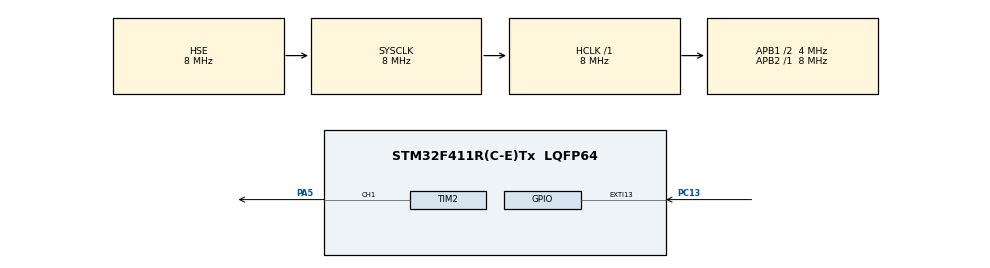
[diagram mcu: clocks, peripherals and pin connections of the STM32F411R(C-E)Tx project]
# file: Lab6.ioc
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Mcu.Family=STM32F4
Mcu.Name=STM32F411R(C-E)Tx
Mcu.Package=LQFP64
NVIC.EXTI15_10_IRQn=true\:0\:0\:false\:false\:true\:true\:true\:true
NVIC.PriorityGroup=NVIC_PRIORITYGROUP_0
NVIC.TIM3_IRQn=true\:0\:0\:false\:false\:true\:true\:true\:true
PA14.GPIO_Label=TCK
PA14.Signal=SYS_JTCK-SWCLK
PA5.Signal=S_TIM2_CH1_ETR
PB3.GPIO_Label=SWO
PB3.Signal=SYS_JTDO-SWO
PC13-ANTI_TAMP.Signal=GPXTI13
PH0\ -\ OSC_IN.Mode=HSE-External-Oscillator
PH0\ -\ OSC_IN.Signal=RCC_OSC_IN
PH1\ -\ OSC_OUT.Mode=HSE-External-Oscillator
PH1\ -\ OSC_OUT.Signal=RCC_OSC_OUT
ProjectManager.HeapSize=0x200
ProjectManager.StackSize=0x400
ProjectManager.TargetToolchain=STM32CubeIDE
RCC.48MHZClocksFreq_Value=25000000
RCC.AHBFreq_Value=8000000
RCC.APB1CLKDivider=RCC_HCLK_DIV2
RCC.APB1Freq_Value=4000000
RCC.APB1TimFreq_Value=8000000
RCC.APB2Freq_Value=8000000
RCC.APB2TimFreq_Value=8000000
RCC.CortexFreq_Value=8000000
RCC.FLatency-AdvancedSettings=FLASH_LATENCY_0
RCC.HCLKFreq_Value=8000000
RCC.HSE_VALUE=8000000
RCC.HSI_VALUE=16000000
RCC.PLLM=8
RCC.PLLN=50
RCC.SYSCLKFreq_VALUE=8000000
RCC.SYSCLKSource=RCC_SYSCLKSOURCE_HSE
RCC.VCOOutputFreq_Value=100000000
SH.S_TIM2_CH1_ETR.0=TIM2_CH1,PWM Generation1 CH1
TIM2.Channel-PWM\ Generation1\ CH1=TIM_CHANNEL_1
TIM2.Period=3999
TIM2.Pulse-PWM\ Generation1\ CH1=0
TIM3.Period=799
TIM3.Prescaler=199
VP_TIM2_VS_ClockSourceINT.Mode=Internal
VP_TIM3_VS_ClockSourceINT.Mode=Internal
board=NUCLEO-F411RE

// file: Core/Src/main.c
/* USER CODE BEGIN Header */
/**
  ******************************************************************************
  * @file           : main.c
  * @brief          : Main program body
  ******************************************************************************
  * @attention
  *
  * Copyright (c) 2026 STMicroelectronics.
  * All rights reserved.
  *
  * This software is licensed under terms that can be found in the LICENSE file
  * in the root directory of this software component.
  * If no LICENSE file comes with this software, it is provided AS-IS.
  *
  ******************************************************************************
  */

/*
 * Варіант 3 (23)
 * Запрограмувати генерацію ШІМ на PA5 (TIM2) з частотою 2 кГц, кнопка PC13 циклічно змінює
duty cycle 0%, 25%, 50%, 75%, 100%

f_pwm = f_tim/((PSC+1)*(ARR+1))
2 000 = 8 000 000/((0+1)*(3999+1))

Duty cycle:
D = CCR1/(ARR+1)

0%
CCR1 = 0
25%
CCR1 = 1000
50%
CCR1 = 2000
75%
CCR1 = 3000
100%
CCR1 = 4000

TIM3 for debounce
T = ((PSK+1)*(ARR+1))/fsck
0.02 = ((199+1)*(799+1))/8 000 000

 */

/* USER CODE END Header */
#include "main.h"

TIM_HandleTypeDef htim2;
TIM_HandleTypeDef htim3;

/* USER CODE BEGIN PV */
uint32_t duty_steps[] = {0, 1000, 2000, 3000, 4000};
int step_index = 0;
int button_pressed_flag = 0;
/* USER CODE END PV */

void SystemClock_Config(void);
static void MX_GPIO_Init(void);
static void MX_TIM2_Init(void);
static void MX_TIM3_Init(void);

/* USER CODE BEGIN 0 */
void HAL_GPIO_EXTI_Callback(uint16_t GPIO_Pin)
{
    if(GPIO_Pin == GPIO_PIN_13)
    {
        if (htim3.State == HAL_TIM_STATE_READY)
        {
            HAL_TIM_Base_Start_IT(&htim3);
        }
    }
}

void HAL_TIM_PeriodElapsedCallback(TIM_HandleTypeDef *htim) {
    if (htim->Instance == TIM3) {
        HAL_TIM_Base_Stop_IT(&htim3);
        button_pressed_flag = 1;
    }
}

/* USER CODE END 0 */

int main(void)
{

  /* MCU Configuration--------------------------------------------------------*/

  /* Reset of all peripherals, Initializes the Flash interface and the Systick. */
  HAL_Init();

  /* Configure the system clock */
  SystemClock_Config();

  /* Initialize all configured peripherals */
  MX_GPIO_Init();
  MX_TIM2_Init();
  MX_TIM3_Init();
  /* USER CODE BEGIN 2 */
  HAL_TIM_PWM_Start(&htim2, TIM_CHANNEL_1);
  /* USER CODE END 2 */

  /* Infinite loop */
  while (1)
  {
    /* USER CODE BEGIN 3 */
	  if(button_pressed_flag)
	  {
		  step_index = (step_index + 1) % 5;
		  __HAL_TIM_SET_COMPARE(&htim2, TIM_CHANNEL_1, duty_steps[step_index]);
		  button_pressed_flag = 0;
	  }
  }
  /* USER CODE END 3 */
}

void SystemClock_Config(void)
{
  RCC_OscInitTypeDef RCC_OscInitStruct = {0};
  RCC_ClkInitTypeDef RCC_ClkInitStruct = {0};

  /** Configure the main internal regulator output voltage
  */
  __HAL_RCC_PWR_CLK_ENABLE();
  __HAL_PWR_VOLTAGESCALING_CONFIG(PWR_REGULATOR_VOLTAGE_SCALE1);

  /** Initializes the RCC Oscillators according to the specified parameters
  * in the RCC_OscInitTypeDef structure.
  */
  RCC_OscInitStruct.OscillatorType = RCC_OSCILLATORTYPE_HSE;
  RCC_OscInitStruct.HSEState = RCC_HSE_ON;
  RCC_OscInitStruct.PLL.PLLState = RCC_PLL_NONE;
  if (HAL_RCC_OscConfig(&RCC_OscInitStruct) != HAL_OK)
  {
    Error_Handler();
  }

  /** Initializes the CPU, AHB and APB buses clocks
  */
  RCC_ClkInitStruct.ClockType = RCC_CLOCKTYPE_HCLK|RCC_CLOCKTYPE_SYSCLK
                              |RCC_CLOCKTYPE_PCLK1|RCC_CLOCKTYPE_PCLK2;
  RCC_ClkInitStruct.SYSCLKSource = RCC_SYSCLKSOURCE_HSE;
  RCC_ClkInitStruct.AHBCLKDivider = RCC_SYSCLK_DIV1;
  RCC_ClkInitStruct.APB1CLKDivider = RCC_HCLK_DIV2;
  RCC_ClkInitStruct.APB2CLKDivider = RCC_HCLK_DIV1;

  if (HAL_RCC_ClockConfig(&RCC_ClkInitStruct, FLASH_LATENCY_0) != HAL_OK)
  {
    Error_Handler();
  }
}

static void MX_TIM2_Init(void)
{

  TIM_ClockConfigTypeDef sClockSourceConfig = {0};
  TIM_MasterConfigTypeDef sMasterConfig = {0};
  TIM_OC_InitTypeDef sConfigOC = {0};

  htim2.Instance = TIM2;
  htim2.Init.Prescaler = 0;
  htim2.Init.CounterMode = TIM_COUNTERMODE_UP;
  htim2.Init.Period = 3999;
  htim2.Init.ClockDivision = TIM_CLOCKDIVISION_DIV1;
  htim2.Init.AutoReloadPreload = TIM_AUTORELOAD_PRELOAD_DISABLE;
  if (HAL_TIM_Base_Init(&htim2) != HAL_OK)
  {
    Error_Handler();
  }
  sClockSourceConfig.ClockSource = TIM_CLOCKSOURCE_INTERNAL;
  if (HAL_TIM_ConfigClockSource(&htim2, &sClockSourceConfig) != HAL_OK)
  {
    Error_Handler();
  }
  if (HAL_TIM_PWM_Init(&htim2) != HAL_OK)
  {
    Error_Handler();
  }
  sMasterConfig.MasterOutputTrigger = TIM_TRGO_RESET;
  sMasterConfig.MasterSlaveMode = TIM_MASTERSLAVEMODE_DISABLE;
  if (HAL_TIMEx_MasterConfigSynchronization(&htim2, &sMasterConfig) != HAL_OK)
  {
    Error_Handler();
  }
  sConfigOC.OCMode = TIM_OCMODE_PWM1;
  sConfigOC.Pulse = 0;
  sConfigOC.OCPolarity = TIM_OCPOLARITY_HIGH;
  sConfigOC.OCFastMode = TIM_OCFAST_DISABLE;
  if (HAL_TIM_PWM_ConfigChannel(&htim2, &sConfigOC, TIM_CHANNEL_1) != HAL_OK)
  {
    Error_Handler();
  }
  HAL_TIM_MspPostInit(&htim2);

}

static void MX_TIM3_Init(void)
{

  TIM_ClockConfigTypeDef sClockSourceConfig = {0};
  TIM_MasterConfigTypeDef sMasterConfig = {0};

  htim3.Instance = TIM3;
  htim3.Init.Prescaler = 199;
  htim3.Init.CounterMode = TIM_COUNTERMODE_UP;
  htim3.Init.Period = 799;
  htim3.Init.ClockDivision = TIM_CLOCKDIVISION_DIV1;
  htim3.Init.AutoReloadPreload = TIM_AUTORELOAD_PRELOAD_DISABLE;
  if (HAL_TIM_Base_Init(&htim3) != HAL_OK)
  {
    Error_Handler();
  }
  sClockSourceConfig.ClockSource = TIM_CLOCKSOURCE_INTERNAL;
  if (HAL_TIM_ConfigClockSource(&htim3, &sClockSourceConfig) != HAL_OK)
  {
    Error_Handler();
  }
  sMasterConfig.MasterOutputTrigger = TIM_TRGO_RESET;
  sMasterConfig.MasterSlaveMode = TIM_MASTERSLAVEMODE_DISABLE;
  if (HAL_TIMEx_MasterConfigSynchronization(&htim3, &sMasterConfig) != HAL_OK)
  {
    Error_Handler();
  }

}

static void MX_GPIO_Init(void)
{
  GPIO_InitTypeDef GPIO_InitStruct = {0};

  /* GPIO Ports Clock Enable */
  __HAL_RCC_GPIOC_CLK_ENABLE();
  __HAL_RCC_GPIOH_CLK_ENABLE();
  __HAL_RCC_GPIOA_CLK_ENABLE();
  __HAL_RCC_GPIOB_CLK_ENABLE();

  /*Configure GPIO pin : PC13 */
  GPIO_InitStruct.Pin = GPIO_PIN_13;
  GPIO_InitStruct.Mode = GPIO_MODE_IT_RISING;
  GPIO_InitStruct.Pull = GPIO_NOPULL;
  HAL_GPIO_Init(GPIOC, &GPIO_InitStruct);

  /* EXTI interrupt init*/
  HAL_NVIC_SetPriority(EXTI15_10_IRQn, 0, 0);
  HAL_NVIC_EnableIRQ(EXTI15_10_IRQn);

}

void Error_Handler(void)
{
  __disable_irq();
  while (1)
  {
  }
}
